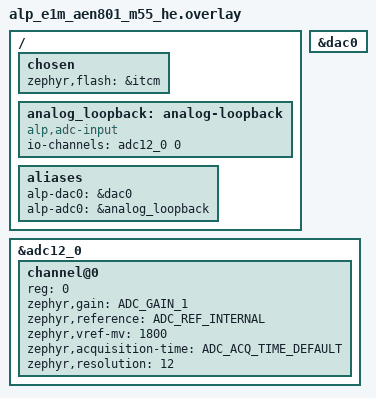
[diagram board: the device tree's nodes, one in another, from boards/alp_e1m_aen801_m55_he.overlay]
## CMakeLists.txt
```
# SPDX-License-Identifier: Apache-2.0
#
# aen-analog-validate -- DAC0 -> ADC loopback on-silicon analog validation for
# the E1M-AEN801 (Ensemble E8, M55-HE), driven through the SoM-portable
# <alp/dac.h> + <alp/adc.h> surface.
#
# board.yaml-driven app (like aen-eeprom-manifest): `tan build` (or
# scripts/gen_example_alp_conf.py for twister / bare `west build`) derives the
# CONFIG_* set (CONFIG_ADC, CONFIG_ALP_SOC_ALIF_ENSEMBLE_E8, ...) from
# board.yaml into generated/alp.conf, layered over prj.conf via
# EXTRA_CONF_FILE.  The
# device-only DT wiring (dac0 + adc12_0 + the alp-dac0/alp-adc0 aliases) lives in
# boards/alp_e1m_aen801_m55_he_ae822fa0e5597ls0_rtss_he.overlay, which Zephyr
# auto-applies by the FULLY-QUALIFIED board name (bare-name overlays are
# silently dropped by `west build -b alp_e1m_aen801_m55_he/.../rtss_he`).

cmake_minimum_required(VERSION 3.20)

find_package(Zephyr REQUIRED HINTS $ENV{ZEPHYR_BASE})
project(aen_analog_validate LANGUAGES C)

target_sources(app PRIVATE src/main.c)
```

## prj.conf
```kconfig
# SPDX-License-Identifier: Apache-2.0
#
# Bench RAM-run config for the E1M-AEN801 (M55-HE). Console is the Alp UART
# console on the E1M edge UART0 (see the console block below).
#
# CONFIG_ALP_SDK + CONFIG_ADC + CONFIG_DAC + CONFIG_ALP_SOC_ALIF_ENSEMBLE_E8 come
# from board.yaml by `tan build` (layered in via EXTRA_CONF_FILE). This
# file only carries what the board.yaml schema can't express.
#
# The Alif "alif,dac" driver needs no line here either: CONFIG_DAC_ALIF is
# `default y` once the dac node is enabled (DT_HAS_ALIF_DAC_ENABLED), and it
# `select`s PINCTRL + USE_ALIF_HAL_ANALOG (the hal_alif analog_ctrl VREF library,
# shared with ADC) itself. Do NOT assign select-only / USE_ALIF_HAL_* symbols.

# Drive the loopback through the SoM-portable <alp/dac.h> + <alp/adc.h> surface
# (NOT the raw Zephyr API). Both dispatchers link here:
#   - The DAC dispatcher + its portable backend (src/backends/dac/zephyr_drv.c)
#     compile unconditionally (zephyr/CMakeLists.txt), so .alp_backends_dac is
#     always non-empty.
#   - The ADC dispatcher (CONFIG_ALP_SDK_PERIPH_ADC, `default y if ADC`) links
#     because the E8 ADC backend (src/backends/adc/alif_e8.c) is gated on
#     CONFIG_ALP_SOC_ALIF_ENSEMBLE_E8 -- which board.yaml sets via the E1M-AEN801
#     SKU -- so .alp_backends_adc is non-empty. (Unlike aen-adc-regcheck, which is
#     a plain prj.conf app with no SoC backend and so must set this OFF.)
# Both are left at their defaults; listed here only as documentation.

# Console: Alp UART console -- E1M edge UART0 (Alif UART5, P3_4/P3_5, 115200
# 8N1, NS16550), the E1M-AEN801 carrier console. The board _defconfig already
# selects it; we set it explicitly here so the example is self-describing.
CONFIG_SERIAL=y
CONFIG_CONSOLE=y
CONFIG_UART_CONSOLE=y
CONFIG_UART_INTERRUPT_DRIVEN=y
# Serial-less bench? Comment the four lines above and uncomment these to read
# 'ram_console_buf' over SWD instead:
# CONFIG_RAM_CONSOLE=y
# CONFIG_RAM_CONSOLE_BUFFER_SIZE=2048
# CONFIG_UART_CONSOLE=n
CONFIG_PRINTK=y

# Keep the image small + deterministic for this bench run.
CONFIG_LOG=n

# Bench: a dep selects LOG (overriding LOG=n); use minimal mode so it routes
# through printk to the console synchronously (deferred log adds buffering).
CONFIG_LOG_MODE_MINIMAL=y
```

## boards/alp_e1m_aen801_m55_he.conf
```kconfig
# SPDX-License-Identifier: Apache-2.0
#
# Board-scoped Kconfig default for aen-analog-validate on the E1M-AEN801
# (M55-HE).  Zephyr auto-applies boards/<board>.conf by board name -- the
# application-level analog of a board Kconfig.defconfig default: it lands only
# when this example is built for alp_e1m_aen801_m55_he, and the user can still
# override it on the command line.
#
# CONFIG_DCACHE=n: the bench RAM-run flow loads the image into ITCM/TCM over
# J-Link and runs without cache maintenance.  The analog converters are MMIO and
# the loopback is a short single-shot, so a data cache buys nothing here; leaving
# it off keeps the RAM-run deterministic and matches the other E8 bench apps
# (aen-npu-inference-alif, aen-ethernet-link).  It is a DEFAULT, not a hard
# requirement -- a flashed (non-RAM-run) build can re-enable it.
CONFIG_DCACHE=n
```

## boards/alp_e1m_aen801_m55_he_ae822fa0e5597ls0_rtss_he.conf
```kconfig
# SPDX-License-Identifier: Apache-2.0
#
# Board-scoped Kconfig default for aen-analog-validate on the E1M-AEN801
# (M55-HE).  Zephyr auto-applies boards/<board>.conf by the FULLY-QUALIFIED
# board id, not the bare board name -- on the customer build (`west build -b
# alp_e1m_aen801_m55_he/ae822fa0e5597ls0/rtss_he`) only a .conf named after
# that full id lands.  The application-level analog of a board
# Kconfig.defconfig default: it applies only when this example is built for
# alp_e1m_aen801_m55_he/ae822fa0e5597ls0/rtss_he, and the user can still
# override it on the command line.
#
# CONFIG_DCACHE=n: the bench RAM-run flow loads the image into ITCM/TCM over
# J-Link and runs without cache maintenance.  The analog converters are MMIO and
# the loopback is a short single-shot, so a data cache buys nothing here; leaving
# it off keeps the RAM-run deterministic and matches the other E8 bench apps
# (aen-npu-inference-alif, aen-ethernet-link).  It is a DEFAULT, not a hard
# requirement -- a flashed (non-RAM-run) build can re-enable it.
CONFIG_DCACHE=n
```

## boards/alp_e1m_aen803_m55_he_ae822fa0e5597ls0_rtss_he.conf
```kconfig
# SPDX-License-Identifier: Apache-2.0
#
# Board-scoped Kconfig default for aen-analog-validate on the E1M-AEN803
# (M55-HE).  Zephyr auto-applies boards/<board>.conf by the FULLY-QUALIFIED
# board id, not the bare board name -- on the customer build (`west build -b
# alp_e1m_aen803_m55_he/ae822fa0e5597ls0/rtss_he`) only a .conf named after
# that full id lands.  The application-level analog of a board
# Kconfig.defconfig default: it applies only when this example is built for
# alp_e1m_aen803_m55_he/ae822fa0e5597ls0/rtss_he, and the user can still
# override it on the command line.
#
# CONFIG_DCACHE=n: the bench RAM-run flow loads the image into ITCM/TCM over
# J-Link and runs without cache maintenance.  The analog converters are MMIO and
# the loopback is a short single-shot, so a data cache buys nothing here; leaving
# it off keeps the RAM-run deterministic and matches the other E8 bench apps
# (aen-npu-inference-alif, aen-ethernet-link).  It is a DEFAULT, not a hard
# requirement -- a flashed (non-RAM-run) build can re-enable it.
CONFIG_DCACHE=n
```

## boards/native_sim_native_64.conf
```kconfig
# SPDX-License-Identifier: Apache-2.0
#
# native_sim portability gate (build_only).  prj.conf turns on the bench RAM
# console (a real-silicon, no-USB-UART artifact); on native_sim CONFIG_RAM_CONSOLE
# pulls a picolibc stdout hook (__stdout_hook_install) that the native console
# does not provide, so the link fails with an undefined reference.  Use the native
# console here instead -- the only point of the native_sim build is that the
# portable <alp/dac.h> + <alp/adc.h> source compiles + links off-target.
CONFIG_RAM_CONSOLE=n
CONFIG_UART_CONSOLE=y
```

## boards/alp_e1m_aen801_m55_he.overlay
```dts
/*
 * Copyright (c) 2026 Alp Lab AB
 * SPDX-License-Identifier: Apache-2.0
 *
 * aen-analog-validate overlay for the E1M-AEN801 (Ensemble E8, M55-HE) RAM-run.
 *
 * DEVICE-ONLY wiring for the DAC0 -> ADC loopback driven through the portable
 * <alp/dac.h> + <alp/adc.h> surface (no Kconfig here -- CONFIG_DCACHE=n is a
 * board Kconfig.defconfig default, CONFIG_ADC/DAC come from board.yaml + prj.conf).
 * Enables:
 *   - dac0    (12-bit DAC @ 0x49028000, alif,dac; output = E1M pad A16 = Alif
 *              P2_2 = DAC_0 per metadata/e1m_modules/aen/from-alif.tsv).
 *              Driver-fixed reference = 0.750 V (DAC12_VREF_CONT=0x4; carried in
 *              the SoC dtsi as alif,reference-mv=750).
 *   - adc12_0 (12-bit SAR @ 0x49020000, alif,adc).  Driver-fixed reference =
 *              1.8 V (ADC_VREF_CONT=0x10, RDIV=0).
 *
 * Both controller nodes carry their reg / reg-names / config props from the SoC
 * dtsi (zephyr/dts/alif/ensemble_e8_peripherals.dtsi, transcribed VERBATIM from
 * the Apache-2.0 zephyr_alif fork e1.dtsi); this overlay flips them okay, adds
 * the io-channel plumbing the portable <alp/adc.h> backend needs, and declares
 * the alp-dac0 / alp-adc0 aliases the portable backends resolve.
 *
 * Portable-alias wiring (this is what differs from the raw-API regcheck overlays):
 *   - The <alp/dac.h> backend does DEVICE_DT_GET(DT_ALIAS(alp_dac0)), so the
 *     alp-dac0 alias points DIRECTLY at the dac0 controller node.
 *   - The <alp/adc.h> backend does ADC_DT_SPEC_GET(DT_ALIAS(alp_adc0)), which
 *     expands to DT_IO_CHANNELS_CTLR/INPUT -- so the alp-adc0 alias must point at
 *     an io-channels CONSUMER node (analog_loopback below), NOT at the controller.
 *     The controller gets a channel@0 child carrying the standard zephyr,* ADC
 *     channel config (the regcheck app builds that config in C; the portable path
 *     reads it from DT).
 *
 * BENCH JUMPER REQUIRED: a wire from the DAC0 pad (A16 / P2_2) to an ANA_S input
 * pad routed to the chosen ADC instance.  The from-alif.tsv routes the analog
 * sense pads as: A12=ANA_S6 A13=ANA_S4 A14=ANA_S2(P0_2) A15=ANA_S0(P0_0)
 * B12=ANA_S7 B13=ANA_S5 B14=ANA_S3(P0_3) B15=ANA_S1(P0_1).
 *
 * TBD (bench unknown, do NOT invent): which ADC12 INSTANCE + CHANNEL INDEX each
 * ANA_S pad lands on is an Alif TRM detail not present in the fetched fork
 * source.  This overlay defaults the alp-adc0 alias to adc12_0 channel 0 (a
 * PLAUSIBLE DEFAULT: ANA_S0 = A15 = P0_0 is the lowest-numbered sense pad).  If
 * the jumper/TRM map says otherwise, repoint analog_loopback's io-channels (and
 * the channel@0 reg) at the right instance/channel.  See README.md.
 */

#include <zephyr/dt-bindings/adc/adc.h>

/*
 * RAM-run: the SoC `select` puts code in XIP; retarget ROM to ITCM so the image
 * links + runs from RAM (J-Link loadbin+go, no reset). PATH-REFERENCE form
 * (&itcm) -- the phandle-array form makes FLASH_SIZE=0 and overflows the link.
 */
/ {
	chosen {
		zephyr,flash = &itcm;
		/delete-property/ zephyr,code-partition;
	};

	/*
	 * io-channels consumer the alp-adc0 alias resolves to.  ADC_DT_SPEC_GET on
	 * the alias reads .dev from the referenced controller (adc12_0) and
	 * .channel_id from the input cell (0), then pulls the channel@0 config.
	 *
	 * compatible = "alp,adc-input" is REQUIRED, not cosmetic.  A binding-LESS
	 * consumer (the shape `zephyr,user` uses) only gets io-channels phandle-array
	 * macros generated because gen_edt.py hard-codes "/zephyr,user" in
	 * infer_binding_for_paths (gen_edt.py:52).  For ANY other path, edtlib's
	 * no-binding fallback only type-infers the fixed _DEFAULT_PROP_TYPES whitelist
	 * (edtlib.py:3653 -- compatible/status/reg/interrupts/..., NO io-channels), so
	 * `io-channels` is silently dropped from node.props and gen_defines emits
	 * neither DT_N_S_analog_loopback_P_io_channels_IDX_0_PH nor ..._VAL_input ->
	 * ADC_DT_SPEC_GET fails to compile.  Giving the node a `compatible` whose
	 * binding (zephyr/dts/bindings/adc/alp,adc-input.yaml) declares io-channels as
	 * `type: phandle-array` makes edtlib build the ControllerAndData, so the
	 * _PH (controller ord) + _VAL_input (cell 0) macros are generated.
	 */
	analog_loopback: analog-loopback {
		compatible = "alp,adc-input";
		io-channels = <&adc12_0 0>;
	};

	aliases {
		/* Portable DAC channel 0 -> the dac0 controller (DEVICE_DT_GET). */
		alp-dac0 = &dac0;
		/* Portable ADC channel 0 -> the io-channels consumer (ADC_DT_SPEC_GET). */
		alp-adc0 = &analog_loopback;
	};
};

&dac0 {
	status = "okay";
};

/*
 * TBD: adc12_0 is the plausible-default loopback receiver.  If the bench jumper
 * lands the DAC0 pad on an ANA_S input owned by adc12_1 / adc12_2, enable that
 * instance instead and repoint analog_loopback's io-channels at it.
 */
&adc12_0 {
	status = "okay";

	/*
	 * Channel 0 config for the portable <alp/adc.h> path (the raw-API regcheck
	 * builds the equivalent adc_channel_cfg in C):
	 *   - zephyr,gain = ADC_GAIN_1: unity (PGA only matters in differential mode).
	 *   - zephyr,reference = ADC_REF_INTERNAL: the driver fixes the ADC reference
	 *     in hardware (ADC_VREF_CONT=0x10, RDIV=0 = 1.8 V); this is the portable
	 *     enum that maps onto it.
	 *   - zephyr,vref-mv = 1800: the ADC full-scale reference in mV.  The
	 *     <alp/adc.h> backend reads this (spec->vref_mv) to convert the raw code
	 *     to microvolts -- it MUST match the 1.8 V the silicon is programmed to
	 *     (adc_alif.c ADC_VREF_CONT=0x10 / RDIV=0 == hal_alif analog_ctrl.h:63/:46).
	 *   - zephyr,acquisition-time = ADC_ACQ_TIME_DEFAULT: the adc_alif driver
	 *     programs the sample-and-hold from its own DT props, so the portable
	 *     channel cfg just asks for the default.
	 *   - zephyr,resolution = 12: 12-bit SAR.
	 *
	 * The controller already declares #address-cells/#size-cells (= <1>/<0>)
	 * in the SoC dtsi, so the channel@0 child resolves without redeclaring them.
	 */
	channel@0 {
		reg = <0>;
		zephyr,gain = "ADC_GAIN_1";
		zephyr,reference = "ADC_REF_INTERNAL";
		zephyr,vref-mv = <1800>;
		zephyr,acquisition-time = <ADC_ACQ_TIME_DEFAULT>;
		zephyr,resolution = <12>;
	};
};
```

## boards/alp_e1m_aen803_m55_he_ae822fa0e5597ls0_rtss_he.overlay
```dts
/*
 * Copyright (c) 2026 Alp Lab AB
 * SPDX-License-Identifier: Apache-2.0
 *
 * aen-analog-validate overlay for the E1M-AEN803 (Ensemble E8, M55-HE) RAM-run.
 *
 * DEVICE-ONLY wiring for the DAC0 -> ADC loopback driven through the portable
 * <alp/dac.h> + <alp/adc.h> surface (no Kconfig here -- CONFIG_DCACHE=n is a
 * board Kconfig.defconfig default, CONFIG_ADC/DAC come from board.yaml + prj.conf).
 * Enables:
 *   - dac0    (12-bit DAC @ 0x49028000, alif,dac; output = E1M pad A16 = Alif
 *              P2_2 = DAC_0 per metadata/e1m_modules/aen/from-alif.tsv).
 *              Driver-fixed reference = 0.750 V (DAC12_VREF_CONT=0x4; carried in
 *              the SoC dtsi as alif,reference-mv=750).
 *   - adc12_0 (12-bit SAR @ 0x49020000, alif,adc).  Driver-fixed reference =
 *              1.8 V (ADC_VREF_CONT=0x10, RDIV=0).
 *
 * Both controller nodes carry their reg / reg-names / config props from the SoC
 * dtsi (zephyr/dts/alif/ensemble_e8_peripherals.dtsi, transcribed VERBATIM from
 * the Apache-2.0 zephyr_alif fork e1.dtsi); this overlay flips them okay, adds
 * the io-channel plumbing the portable <alp/adc.h> backend needs, and declares
 * the alp-dac0 / alp-adc0 aliases the portable backends resolve.
 *
 * Portable-alias wiring (this is what differs from the raw-API regcheck overlays):
 *   - The <alp/dac.h> backend does DEVICE_DT_GET(DT_ALIAS(alp_dac0)), so the
 *     alp-dac0 alias points DIRECTLY at the dac0 controller node.
 *   - The <alp/adc.h> backend does ADC_DT_SPEC_GET(DT_ALIAS(alp_adc0)), which
 *     expands to DT_IO_CHANNELS_CTLR/INPUT -- so the alp-adc0 alias must point at
 *     an io-channels CONSUMER node (analog_loopback below), NOT at the controller.
 *     The controller gets a channel@0 child carrying the standard zephyr,* ADC
 *     channel config (the regcheck app builds that config in C; the portable path
 *     reads it from DT).
 *
 * BENCH JUMPER REQUIRED: a wire from the DAC0 pad (A16 / P2_2) to an ANA_S input
 * pad routed to the chosen ADC instance.  The from-alif.tsv routes the analog
 * sense pads as: A12=ANA_S6 A13=ANA_S4 A14=ANA_S2(P0_2) A15=ANA_S0(P0_0)
 * B12=ANA_S7 B13=ANA_S5 B14=ANA_S3(P0_3) B15=ANA_S1(P0_1).
 *
 * TBD (bench unknown, do NOT invent): which ADC12 INSTANCE + CHANNEL INDEX each
 * ANA_S pad lands on is an Alif TRM detail not present in the fetched fork
 * source.  This overlay defaults the alp-adc0 alias to adc12_0 channel 0 (a
 * PLAUSIBLE DEFAULT: ANA_S0 = A15 = P0_0 is the lowest-numbered sense pad).  If
 * the jumper/TRM map says otherwise, repoint analog_loopback's io-channels (and
 * the channel@0 reg) at the right instance/channel.  See README.md.
 */

#include <zephyr/dt-bindings/adc/adc.h>

/*
 * RAM-run: the SoC `select` puts code in XIP; retarget ROM to ITCM so the image
 * links + runs from RAM (J-Link loadbin+go, no reset). PATH-REFERENCE form
 * (&itcm) -- the phandle-array form makes FLASH_SIZE=0 and overflows the link.
 */
/ {
	chosen {
		zephyr,flash = &itcm;
		/delete-property/ zephyr,code-partition;
	};

	/*
	 * io-channels consumer the alp-adc0 alias resolves to.  ADC_DT_SPEC_GET on
	 * the alias reads .dev from the referenced controller (adc12_0) and
	 * .channel_id from the input cell (0), then pulls the channel@0 config.
	 *
	 * compatible = "alp,adc-input" is REQUIRED, not cosmetic.  A binding-LESS
	 * consumer (the shape `zephyr,user` uses) only gets io-channels phandle-array
	 * macros generated because gen_edt.py hard-codes "/zephyr,user" in
	 * infer_binding_for_paths (gen_edt.py:52).  For ANY other path, edtlib's
	 * no-binding fallback only type-infers the fixed _DEFAULT_PROP_TYPES whitelist
	 * (edtlib.py:3653 -- compatible/status/reg/interrupts/..., NO io-channels), so
	 * `io-channels` is silently dropped from node.props and gen_defines emits
	 * neither DT_N_S_analog_loopback_P_io_channels_IDX_0_PH nor ..._VAL_input ->
	 * ADC_DT_SPEC_GET fails to compile.  Giving the node a `compatible` whose
	 * binding (zephyr/dts/bindings/adc/alp,adc-input.yaml) declares io-channels as
	 * `type: phandle-array` makes edtlib build the ControllerAndData, so the
	 * _PH (controller ord) + _VAL_input (cell 0) macros are generated.
	 */
	analog_loopback: analog-loopback {
		compatible = "alp,adc-input";
		io-channels = <&adc12_0 0>;
	};

	aliases {
		/* Portable DAC channel 0 -> the dac0 controller (DEVICE_DT_GET). */
		alp-dac0 = &dac0;
		/* Portable ADC channel 0 -> the io-channels consumer (ADC_DT_SPEC_GET). */
		alp-adc0 = &analog_loopback;
	};
};

&dac0 {
	status = "okay";
};

/*
 * TBD: adc12_0 is the plausible-default loopback receiver.  If the bench jumper
 * lands the DAC0 pad on an ANA_S input owned by adc12_1 / adc12_2, enable that
 * instance instead and repoint analog_loopback's io-channels at it.
 */
&adc12_0 {
	status = "okay";

	/*
	 * Channel 0 config for the portable <alp/adc.h> path (the raw-API regcheck
	 * builds the equivalent adc_channel_cfg in C):
	 *   - zephyr,gain = ADC_GAIN_1: unity (PGA only matters in differential mode).
	 *   - zephyr,reference = ADC_REF_INTERNAL: the driver fixes the ADC reference
	 *     in hardware (ADC_VREF_CONT=0x10, RDIV=0 = 1.8 V); this is the portable
	 *     enum that maps onto it.
	 *   - zephyr,vref-mv = 1800: the ADC full-scale reference in mV.  The
	 *     <alp/adc.h> backend reads this (spec->vref_mv) to convert the raw code
	 *     to microvolts -- it MUST match the 1.8 V the silicon is programmed to
	 *     (adc_alif.c ADC_VREF_CONT=0x10 / RDIV=0 == hal_alif analog_ctrl.h:63/:46).
	 *   - zephyr,acquisition-time = ADC_ACQ_TIME_DEFAULT: the adc_alif driver
	 *     programs the sample-and-hold from its own DT props, so the portable
	 *     channel cfg just asks for the default.
	 *   - zephyr,resolution = 12: 12-bit SAR.
	 *
	 * The controller already declares #address-cells/#size-cells (= <1>/<0>)
	 * in the SoC dtsi, so the channel@0 child resolves without redeclaring them.
	 */
	channel@0 {
		reg = <0>;
		zephyr,gain = "ADC_GAIN_1";
		zephyr,reference = "ADC_REF_INTERNAL";
		zephyr,vref-mv = <1800>;
		zephyr,acquisition-time = <ADC_ACQ_TIME_DEFAULT>;
		zephyr,resolution = <12>;
	};
};
```

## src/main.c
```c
/*
 * Copyright (c) 2026 Alp Lab AB
 * SPDX-License-Identifier: Apache-2.0
 *
 * aen-analog-validate -- on-silicon DAC0 -> ADC loopback validation for the
 * E1M-AEN801 (Ensemble E8, M55-HE), driven entirely through the SoM-portable
 * <alp/dac.h> + <alp/adc.h> surface (NOT the raw Zephyr DAC/ADC API).
 *
 * This is the teaching companion to aen-dac-regcheck / aen-adc-regcheck: those
 * two prove the vendored drivers PROGRAM their registers (no analog path) over
 * the raw Zephyr API; this one closes the analog loop AND shows the portable
 * surface a customer actually writes against.  It drives a known millivolt
 * setpoint on dac0 and reads it back through an adc12 instance, asserting the
 * readback tracks the setpoint within tolerance.
 *
 * Why the portable API makes this SIMPLER than the raw-API sibling
 * ---------------------------------------------------------------
 * The two converters run at DIFFERENT, register-fixed references:
 *   - DAC0  : 0.750 V full-scale (DAC12_VREF_CONT=0x4; carried in DT as
 *             alif,reference-mv=750, consumed by the <alp/dac.h> backend's
 *             mv->code conversion).
 *   - adc12 : 1.8 V full-scale (ADC_VREF_CONT=0x10, RDIV=0; carried in the
 *             overlay's channel@0 zephyr,vref-mv=1800, consumed by the
 *             <alp/adc.h> backend's code->uV conversion).
 *
 * With the RAW API the app had to hand-derive the expected ADC raw code from
 * the two VREF register codes (a "VREF-ratio" computation).  The PORTABLE API
 * already carries each converter's reference in DT, so:
 *   - alp_dac_write_mv(dac, V)  drives V millivolts at the DAC's 0.750 V VREF,
 *   - alp_adc_read_uv(adc, &uv) returns the reading already scaled to microvolts
 *     at the ADC's 1.8 V VREF.
 * The loopback check is therefore a DIRECT voltage match -- "did the ADC read
 * back (approximately) the voltage the DAC drove?" -- with no ratio math in the
 * app at all.  The VREF bookkeeping lives once, in DT + the backends.
 *
 * This is still a TRACK check, not an absolute-accuracy spec: the DAC output
 * buffer offset/gain, the ADC input buffer, source impedance and trim all shift
 * the absolute reading -- so the tolerance is deliberately GENEROUS and the gate
 * is "the loopback tracks the setpoint", not "accurate to N mV".
 *
 * BENCH JUMPER REQUIRED: wire the DAC0 pad (E1M A16 = Alif P2_2 = DAC_0, per
 * metadata/e1m_modules/aen/from-alif.tsv) to the ANA_S input pad routed to the
 * ADC instance/channel the alp-adc0 alias resolves to.  The exact
 * ANA_S->instance/channel map is a TRM detail not in the fetched fork source --
 * see README.md + the overlay.  The defaults (alp-adc0 -> adc12_0 channel 0,
 * alp-dac0 -> dac0) are a PLAUSIBLE PICK, not a verified route.
 */

#include <stdbool.h>
#include <stdint.h>

#include <zephyr/kernel.h>
#include <zephyr/sys/printk.h>

#include <alp/dac.h>
#include <alp/adc.h>
#include <alp/peripheral.h>

/*
 * Portable channel indices.  alp_dac_open()/alp_adc_open() resolve these to the
 * alp-dac<N> / alp-adc<N> devicetree aliases the board overlay declares
 * (alp-dac0 -> &dac0, alp-adc0 -> the io-channels consumer pointing at
 * &adc12_0 channel 0).  channel 0 of each is the loopback pair.
 */
#define DAC_CHANNEL 0u
#define ADC_CHANNEL 0u

/*
 * DAC setpoint, in millivolts.  Chosen near mid-scale of the DAC's 0.750 V VREF
 * (~375 mV) so the loopback sits well away from both rails -- away from 0 V and
 * from the DAC buffer's near-rail compression -- where the relationship is
 * cleanest.  alp_dac_write_mv() saturates at the DAC reference, so a value above
 * 750 would just rail; 375 keeps margin on both sides.
 */
#define DAC_SETPOINT_MV 375u

/*
 * PASS tolerance, in microvolts.  The check is a TRACK match, not an absolute
 * accuracy spec -- buffer offset/gain, source impedance and trim all shift the
 * reading -- so the window is generous: +/-120 mV = 120000 uV.  At the ADC's
 * 1.8 V / 4096-code span that is ~+/-273 LSB, comparable to the raw-API
 * sibling's +/-256 LSB gate.  This still catches a gross failure (dead DAC, open
 * jumper, wrong channel -> floating pad) while not flagging a real-but-offset
 * loopback.  TBD: exact bench-verified window once the converters are
 * characterised.
 */
#define TOLERANCE_UV 120000

int main(void)
{
	printk("\n=== aen-analog-validate (DAC0 -> ADC loopback, <alp/*> API) ===\n");
	printk("dac channel: %u (alp-dac%u alias)  setpoint %u mV\n",
	       DAC_CHANNEL,
	       DAC_CHANNEL,
	       DAC_SETPOINT_MV);
	printk("adc channel: %u (alp-adc%u alias)  [INSTANCE/CH is TBD -- see README]\n",
	       ADC_CHANNEL,
	       ADC_CHANNEL);

	/*
	 * --- drive the DAC through <alp/dac.h> -----------------------------
	 * alp_dac_open() borrows a handle, brings the channel up at 12-bit, and
	 * (initial_mv != 0) primes the output to the setpoint in one call -- the
	 * mv->code conversion uses the channel's DT alif,reference-mv (0.750 V).
	 */
	alp_dac_t *dac = alp_dac_open(&(alp_dac_config_t){
	    .channel_id = DAC_CHANNEL,
	    .initial_mv = DAC_SETPOINT_MV,
	});
	if (dac == NULL) {
		printk("RESULT FAIL: alp_dac_open failed (alp_last_error=%d; "
		       "expected NOT_READY=-2 if dac0 not okay'd / clock / VREF)\n",
		       (int)alp_last_error());
		return 0;
	}

	/* Read the setpoint back from the SDK-side cache so the log shows what the
	 * DAC was actually programmed to (saturated at the reference rail). */
	uint16_t     dac_mv = 0;
	alp_status_t s_rd   = alp_dac_read_mv(dac, &dac_mv);
	printk("alp_dac: programmed %u mV (read_mv status=%d)\n", dac_mv, (int)s_rd);

	/*
	 * Let the DAC output buffer + jumper RC settle before sampling.  The exact
	 * settling time is load-dependent (bench unknown); 5 ms is comfortably long
	 * for a short jumper into the ADC input.
	 */
	k_msleep(5);

	/*
	 * --- read it back through <alp/adc.h> ------------------------------
	 * alp_adc_open() resolves the alp-adc0 alias to its io-channels spec,
	 * applies the channel config, and returns a handle.  resolution_bits=0
	 * means "use the DT channel default" (12-bit here).
	 */
	alp_adc_t *adc = alp_adc_open(&(alp_adc_config_t){
	    .channel_id      = ADC_CHANNEL,
	    .resolution_bits = 0,
	    .reference       = ALP_ADC_REF_INTERNAL,
	});
	if (adc == NULL) {
		printk("RESULT FAIL: alp_adc_open failed (alp_last_error=%d; "
		       "expected NOT_READY=-2 if adc12_0 not okay'd / no channel@0)\n",
		       (int)alp_last_error());
		alp_dac_close(dac);
		return 0;
	}

	/*
	 * alp_adc_read_uv() returns the reading already converted to microvolts at
	 * the ADC's DT reference (1.8 V here) -- so it is directly comparable to the
	 * DAC setpoint in the same voltage domain.  No ratio math in the app.
	 */
	int32_t      adc_uv = 0;
	alp_status_t s_adc  = alp_adc_read_uv(adc, &adc_uv);
	printk("alp_adc: read_uv status=%d, measured %d uV (%d mV)\n",
	       (int)s_adc,
	       (int)adc_uv,
	       (int)(adc_uv / 1000));

	/* --- compare in the microvolt domain ------------------------------- */
	int32_t  setpoint_uv = (int32_t)dac_mv * 1000;
	int32_t  err_uv      = adc_uv - setpoint_uv;
	uint32_t abs_err_uv  = (uint32_t)((err_uv < 0) ? -err_uv : err_uv);

	printk("-- loopback --\n");
	printk("DAC drove   : %d uV (%u mV setpoint)\n", setpoint_uv, dac_mv);
	printk("ADC read    : %d uV\n", adc_uv);
	printk("error       : %d uV (|err| %u, tol +/-%d uV)\n", err_uv, abs_err_uv, TOLERANCE_UV);

	/*
	 * PASS gate = the whole loop works: every call succeeded (DAC readback AND
	 * ADC read -- a failed alp_dac_read_mv leaves dac_mv at 0, which would turn
	 * the setpoint into 0 uV and make the comparison meaningless) AND the ADC
	 * reading lands within +/-TOLERANCE_UV of the DAC setpoint.  An open jumper,
	 * a wrong ADC channel or a dead DAC leaves the ADC on a floating pad, so the
	 * track check is what makes this a real analog test.
	 *
	 * Which adc12 instance+channel the DAC0 pad (A16/P2_2) lands on is a
	 * TRM/jumper value (BENCH-TBD, NOT invented; this example reads adc12_0 ch0,
	 * a plausible default), so an OUT-OF-TOL FAIL names the route as the first
	 * thing to check.  No absolute-accuracy claim: the tolerance is generous.
	 */
	bool calls_ok = (s_rd == ALP_OK) && (s_adc == ALP_OK);
	bool track_ok = (abs_err_uv <= (uint32_t)TOLERANCE_UV);

	if (calls_ok && track_ok) {
		printk("RESULT PASS: portable <alp/*> analog loopback tracks on E8 -- "
		       "alp_dac programmed %d uV + alp_adc read %d uV "
		       "(|err|=%u, tol +/-%d uV)\n",
		       setpoint_uv,
		       adc_uv,
		       abs_err_uv,
		       TOLERANCE_UV);
	} else if (!calls_ok) {
		printk("RESULT FAIL: portable analog API call did not succeed "
		       "(dac_read=%d adc_read=%d setpoint=%d uV)\n",
		       (int)s_rd,
		       (int)s_adc,
		       setpoint_uv);
	} else {
		printk("RESULT FAIL: loopback OUT-OF-TOL -- alp_dac programmed %d uV, alp_adc read "
		       "%d uV (|err|=%u, tol +/-%d uV); check the DAC0->ADC pad/channel route "
		       "(BENCH-TBD) and the jumper\n",
		       setpoint_uv,
		       adc_uv,
		       abs_err_uv,
		       TOLERANCE_UV);
	}

	alp_adc_close(adc);
	alp_dac_close(dac);
	return 0;
}
```
